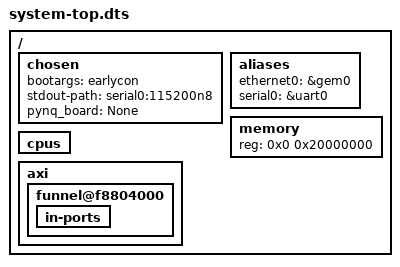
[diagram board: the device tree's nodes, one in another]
/*
 * CAUTION: This file is automatically generated by Xilinx.
 * Version: XSCT 
 * Today is: Thu Jan  4 12:03:40 2024
 */


/dts-v1/;
#include "zynq-7000.dtsi"
#include "pcw.dtsi"
/ {
	chosen {
		bootargs = "earlycon";
		stdout-path = "serial0:115200n8";
	};
	aliases {
		ethernet0 = &gem0;
		serial0 = &uart0;
	};
	memory {
		device_type = "memory";
		reg = <0x0 0x20000000>;
	};
	cpus {
		/delete-node/ cpu@1 ;
	};
	axi {
		/delete-node/ ptm@f889d000 ;

		funnel@f8804000 {
			in-ports {
				/delete-node/ port@1 ;
			};
		};
	};
};
#include "system-user.dtsi"
/include/ "pynq_zynq.dtsi"
/include/ "pynq_uio_zynq.dtsi"
/include/ "pynq_zocl_poll_zynq.dtsi"
/ { chosen { pynq_board = "None"; }; };
